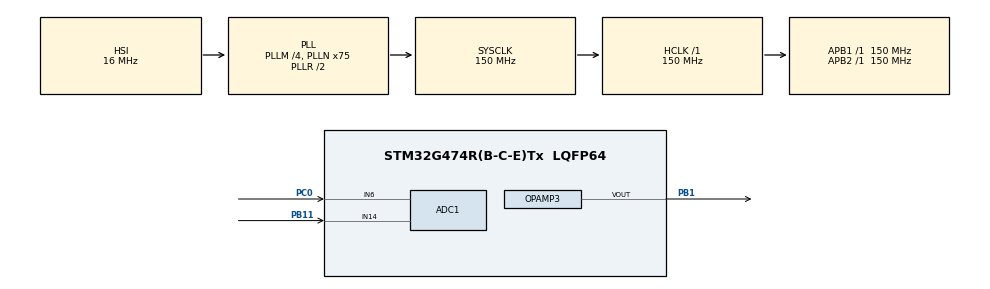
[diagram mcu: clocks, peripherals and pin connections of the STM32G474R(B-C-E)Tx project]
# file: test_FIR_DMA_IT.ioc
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ADC1.Channel-0\#ChannelRegularConversion=ADC_CHANNEL_6
ADC1.ClockPrescaler=ADC_CLOCK_SYNC_PCLK_DIV2
ADC1.DMAContinuousRequests=ENABLE
ADC1.ExternalTrigConv=ADC_EXTERNALTRIG_T1_TRGO
ADC1.GainCompensation=0
ADC1.NbrOfConversionFlag=1
ADC1.OffsetNumber-0\#ChannelRegularConversion=ADC_OFFSET_NONE
ADC1.Overrun=ADC_OVR_DATA_OVERWRITTEN
ADC1.Rank-0\#ChannelRegularConversion=1
ADC1.SamplingTime-0\#ChannelRegularConversion=ADC_SAMPLETIME_47CYCLES_5
ADC1.master=1
DAC3.DAC_Channel-DAC_OUT2_Int=DAC_CHANNEL_2
DAC3.DAC_Trigger_OUT2-DAC_OUT2_Int=DAC_TRIGGER_T1_TRGO
Dma.ADC1.2.Direction=DMA_PERIPH_TO_MEMORY
Dma.ADC1.2.EventEnable=DISABLE
Dma.ADC1.2.Instance=DMA1_Channel4
Dma.ADC1.2.MemDataAlignment=DMA_MDATAALIGN_HALFWORD
Dma.ADC1.2.MemInc=DMA_MINC_ENABLE
Dma.ADC1.2.Mode=DMA_CIRCULAR
Dma.ADC1.2.PeriphDataAlignment=DMA_PDATAALIGN_HALFWORD
Dma.ADC1.2.PeriphInc=DMA_PINC_DISABLE
Dma.ADC1.2.Polarity=HAL_DMAMUX_REQ_GEN_RISING
Dma.ADC1.2.Priority=DMA_PRIORITY_HIGH
Dma.ADC1.2.RequestNumber=1
Dma.ADC1.2.SignalID=NONE
Dma.ADC1.2.SyncEnable=DISABLE
Dma.ADC1.2.SyncPolarity=HAL_DMAMUX_SYNC_NO_EVENT
Dma.ADC1.2.SyncRequestNumber=1
Dma.ADC1.2.SyncSignalID=NONE
Dma.DAC3_CH2.3.Direction=DMA_MEMORY_TO_PERIPH
Dma.DAC3_CH2.3.EventEnable=DISABLE
Dma.DAC3_CH2.3.Instance=DMA1_Channel1
Dma.DAC3_CH2.3.MemDataAlignment=DMA_MDATAALIGN_HALFWORD
Dma.DAC3_CH2.3.MemInc=DMA_MINC_ENABLE
Dma.DAC3_CH2.3.Mode=DMA_CIRCULAR
Dma.DAC3_CH2.3.PeriphDataAlignment=DMA_PDATAALIGN_WORD
Dma.DAC3_CH2.3.PeriphInc=DMA_PINC_DISABLE
Dma.DAC3_CH2.3.Polarity=HAL_DMAMUX_REQ_GEN_RISING
Dma.DAC3_CH2.3.Priority=DMA_PRIORITY_VERY_HIGH
Dma.DAC3_CH2.3.RequestNumber=1
Dma.DAC3_CH2.3.SignalID=NONE
Dma.DAC3_CH2.3.SyncEnable=DISABLE
Dma.DAC3_CH2.3.SyncPolarity=HAL_DMAMUX_SYNC_NO_EVENT
Dma.DAC3_CH2.3.SyncRequestNumber=1
Dma.DAC3_CH2.3.SyncSignalID=NONE
Dma.FMAC_PRELOAD.0.Direction=DMA_MEMORY_TO_MEMORY
Dma.FMAC_PRELOAD.0.EventEnable=DISABLE
Dma.FMAC_PRELOAD.0.Instance=DMA1_Channel3
Dma.FMAC_PRELOAD.0.MemDataAlignment=DMA_MDATAALIGN_WORD
Dma.FMAC_PRELOAD.0.MemInc=DMA_MINC_DISABLE
Dma.FMAC_PRELOAD.0.Mode=DMA_NORMAL
Dma.FMAC_PRELOAD.0.PeriphDataAlignment=DMA_PDATAALIGN_HALFWORD
Dma.FMAC_PRELOAD.0.PeriphInc=DMA_PINC_ENABLE
Dma.FMAC_PRELOAD.0.Polarity=HAL_DMAMUX_REQ_GEN_RISING
Dma.FMAC_PRELOAD.0.Priority=DMA_PRIORITY_HIGH
Dma.FMAC_PRELOAD.0.RequestNumber=1
Dma.FMAC_PRELOAD.0.SignalID=NONE
Dma.FMAC_PRELOAD.0.SyncEnable=DISABLE
Dma.FMAC_PRELOAD.0.SyncPolarity=HAL_DMAMUX_SYNC_NO_EVENT
Dma.FMAC_PRELOAD.0.SyncRequestNumber=1
Dma.FMAC_PRELOAD.0.SyncSignalID=NONE
Dma.FMAC_WRITE.1.Direction=DMA_MEMORY_TO_PERIPH
Dma.FMAC_WRITE.1.EventEnable=DISABLE
Dma.FMAC_WRITE.1.Instance=DMA1_Channel2
Dma.FMAC_WRITE.1.MemDataAlignment=DMA_MDATAALIGN_HALFWORD
Dma.FMAC_WRITE.1.MemInc=DMA_MINC_ENABLE
Dma.FMAC_WRITE.1.Mode=DMA_NORMAL
Dma.FMAC_WRITE.1.PeriphDataAlignment=DMA_PDATAALIGN_WORD
Dma.FMAC_WRITE.1.PeriphInc=DMA_PINC_DISABLE
Dma.FMAC_WRITE.1.Polarity=HAL_DMAMUX_REQ_GEN_RISING
Dma.FMAC_WRITE.1.Priority=DMA_PRIORITY_HIGH
Dma.FMAC_WRITE.1.RequestNumber=1
Dma.FMAC_WRITE.1.SignalID=NONE
Dma.FMAC_WRITE.1.SyncEnable=DISABLE
Dma.FMAC_WRITE.1.SyncPolarity=HAL_DMAMUX_SYNC_NO_EVENT
Dma.FMAC_WRITE.1.SyncRequestNumber=1
Dma.FMAC_WRITE.1.SyncSignalID=NONE
Dma.Request0=FMAC_PRELOAD
Dma.Request1=FMAC_WRITE
Dma.Request2=ADC1
Dma.Request3=DAC3_CH2
Mcu.Family=STM32G4
Mcu.Name=STM32G474R(B-C-E)Tx
Mcu.Package=LQFP64
NVIC.DMA1_Channel1_IRQn=true\:0\:0\:false\:false\:true\:false\:true
NVIC.DMA1_Channel2_IRQn=true\:0\:0\:false\:false\:true\:false\:true
NVIC.DMA1_Channel3_IRQn=true\:0\:0\:false\:false\:true\:false\:true
NVIC.DMA1_Channel4_IRQn=true\:0\:0\:false\:false\:true\:false\:true
NVIC.FMAC_IRQn=true\:0\:0\:false\:false\:true\:true\:true
NVIC.PriorityGroup=NVIC_PRIORITYGROUP_4
OPAMP3.PowerMode=OPAMP_POWERMODE_HIGHSPEED
PB1.Mode=Follower-DAC_OUT2-INP
PB1.Signal=OPAMP3_VOUT
PB11.Mode=IN14-Single-Ended
PB11.Signal=ADC1_IN14
PC0.Mode=IN6-Single-Ended
PC0.Signal=ADC1_IN6
ProjectManager.HeapSize=0x200
ProjectManager.StackSize=0x400
ProjectManager.TargetToolchain=MDK-ARM V5.27
RCC.ADC12Freq_Value=150000000
RCC.ADC345Freq_Value=150000000
RCC.AHBFreq_Value=150000000
RCC.APB1Freq_Value=150000000
RCC.APB1TimFreq_Value=150000000
RCC.APB2Freq_Value=150000000
RCC.APB2TimFreq_Value=150000000
RCC.CortexFreq_Value=150000000
RCC.EXTERNAL_CLOCK_VALUE=12288000
RCC.HCLKFreq_Value=150000000
RCC.HSE_VALUE=24000000
RCC.HSI48_VALUE=48000000
RCC.HSI_VALUE=16000000
RCC.LSE_VALUE=32768
RCC.PLLM=RCC_PLLM_DIV4
RCC.PLLN=75
RCC.SYSCLKFreq_VALUE=150000000
RCC.SYSCLKSource=RCC_SYSCLKSOURCE_PLLCLK
RCC.USBFreq_Value=150000000
RCC.VCOOutputFreq_Value=300000000
TIM1.PeriodNoDither=49
TIM1.Prescaler=14
TIM1.TIM_MasterOutputTrigger=TIM_TRGO_UPDATE
VP_DAC3_VS_DACI2.Mode=DAC_OUT2_Int
VP_FMAC_VS_FMAC.Mode=FMAC_Activate
VP_SYS_VS_DBSignals.Mode=DisableDeadBatterySignals
VP_TIM1_VS_ClockSourceINT.Mode=Internal
board=custom

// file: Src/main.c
/* USER CODE BEGIN Header */
/**
  ******************************************************************************
  * @file           : main.c
  * @brief          : Main program body
  ******************************************************************************
  * @attention
  *
  * <h2><center>&copy; Copyright (c) 2020 STMicroelectronics.
  * All rights reserved.</center></h2>
  *
  * This software component is licensed by ST under BSD 3-Clause license,
  * the "License"; You may not use this file except in compliance with the
  * License. You may obtain a copy of the License at:
  *                        opensource.org/licenses/BSD-3-Clause
  *
  ******************************************************************************
  */
/* USER CODE END Header */

#include "main.h"

/* USER CODE BEGIN Includes */
#include "stm32g4xx_nucleo.h"
#include "private_vars.h"
/* USER CODE END Includes */

/* USER CODE BEGIN PD */
/* Definitions of environment analog values */
  /* Value of analog reference voltage (Vref+), connected to analog voltage   */
  /* supply Vdda (unit: mV).                                                  */
  #define VDDA_APPLI                       (3300U)
/* USER CODE END PD */

ADC_HandleTypeDef hadc1;
DMA_HandleTypeDef hdma_adc1;

DAC_HandleTypeDef hdac3;
DMA_HandleTypeDef hdma_dac3_ch2;

FMAC_HandleTypeDef hfmac;
DMA_HandleTypeDef hdma_fmac_preload;
DMA_HandleTypeDef hdma_fmac_write;

OPAMP_HandleTypeDef hopamp3;

TIM_HandleTypeDef htim1;

/* USER CODE BEGIN PV */
/* FMAC configuration structure */
FMAC_FilterConfigTypeDef sFmacConfig;

/* USER CODE END PV */

void SystemClock_Config(void);
static void MX_GPIO_Init(void);
static void MX_DMA_Init(void);
static void MX_FMAC_Init(void);
static void MX_ADC1_Init(void);
static void MX_DAC3_Init(void);
static void MX_OPAMP3_Init(void);
static void MX_TIM1_Init(void);

int main(void)
{

  /* MCU Configuration--------------------------------------------------------*/

  /* Reset of all peripherals, Initializes the Flash interface and the Systick. */
  HAL_Init();

  /* Configure the system clock */
  SystemClock_Config();

  /* USER CODE BEGIN SysInit */
  /* Configure LED2 */
  BSP_LED_Init(LED2);
  /* USER CODE END SysInit */

  /* Initialize all configured peripherals */
  MX_GPIO_Init();
  MX_DMA_Init();
  MX_FMAC_Init();
  MX_ADC1_Init();
  MX_DAC3_Init();
  MX_OPAMP3_Init();
  MX_TIM1_Init();
  /* USER CODE BEGIN 2 */
  /**********************--======  FMAC  ======--***********************/
  /*## Configure the FMAC peripheral ###########################################*/
  sFmacConfig.InputBaseAddress  = INPUT_BUFFER_BASE;
  sFmacConfig.InputBufferSize   = INPUT_BUFFER_SIZE;
  sFmacConfig.InputThreshold    = INPUT_THRESHOLD;
  sFmacConfig.CoeffBaseAddress  = COEFFICIENT_BUFFER_BASE;
  sFmacConfig.CoeffBufferSize   = COEFFICIENT_BUFFER_SIZE;
  sFmacConfig.OutputBaseAddress = OUTPUT_BUFFER_BASE;
  sFmacConfig.OutputBufferSize  = OUTPUT_BUFFER_SIZE;
  sFmacConfig.OutputThreshold   = OUTPUT_THRESHOLD;
  sFmacConfig.pCoeffA           = NULL;
  sFmacConfig.CoeffASize        = 0;
  sFmacConfig.pCoeffB           = aFilterCoeffB;
  sFmacConfig.CoeffBSize        = COEFF_VECTOR_B_SIZE;
  sFmacConfig.Filter            = FMAC_FUNC_CONVO_FIR;
  sFmacConfig.InputAccess       = FMAC_BUFFER_ACCESS_DMA;
  sFmacConfig.OutputAccess      = FMAC_BUFFER_ACCESS_IT;
#if defined(CLIP_ENABLED)
  sFmacConfig.Clip              = FMAC_CLIP_ENABLED;
#else
  sFmacConfig.Clip              = FMAC_CLIP_DISABLED;
#endif
  sFmacConfig.P                 = COEFF_VECTOR_B_SIZE;
  sFmacConfig.Q                 = FILTER_PARAM_Q_NOT_USED;
  sFmacConfig.R                 = GAIN;

  if (HAL_FMAC_FilterConfig_DMA(&hfmac, &sFmacConfig) != HAL_OK)
  {
    /* Configuration Error */
    Error_Handler();
  }

  while(FilterConfigCallbackCount == 0);

  /*## Preload the dummy input ####################################*/
  if (HAL_FMAC_FilterPreload_DMA(&hfmac, aInputDummyValues, INPUT_DUMMY_ARRAY_SIZE, NULL, 0) != HAL_OK)
  {
    /* Configuration Error */
    Error_Handler();
  }

  while(FilterPreloadCallbackCount == 0);

  /*  Before starting a new process, you need to check the current state of the peripheral;
      if it's busy you need to wait for the end of current transfer before starting the calculation.
      For simplicity reasons, this example is just waiting till the end of the
      process, but the application may perform other tasks while the transfer is ongoing. */
  while (HAL_FMAC_GetState(&hfmac) != HAL_FMAC_STATE_READY)
  {
  }

  /*## Start calculation of FIR filter in DMA/IT mode ##########################*/
  ExpectedCalculatedFilteredDataSize = ADC_BUF_LENGTH / 2;
  if (HAL_FMAC_FilterStart(&hfmac, uhFilteredData, &ExpectedCalculatedFilteredDataSize) != HAL_OK)
  {
    /* Processing Error */
    Error_Handler();
  }

  /**********************--======  ADCs  ======--***********************/
//  uhADCxConvertedData = VAR_CONVERTED_DATA_INIT_VALUE;
  /* Run the ADC calibration in single-ended mode */
  if (HAL_ADCEx_Calibration_Start(&hadc1, ADC_SINGLE_ENDED) != HAL_OK)
  {
    /* Calibration Error */
    Error_Handler();
  }
  /*## Start ADC conversions ###############################################*/
  /* Start ADC group regular conversion with DMA */
  if (HAL_ADC_Start_DMA(&hadc1, (uint32_t *)uhADCxConvertedData, ADC_BUF_LENGTH ) != HAL_OK)
  {
    /* ADC conversion start error */
    Error_Handler();
  }

  /* Start DAC conversion with DMA */
  if (HAL_DAC_Start_DMA(&hdac3, DAC_CHANNEL_2, (uint32_t *)uhFilteredData, ADC_BUF_LENGTH, DAC_ALIGN_12B_R ) != HAL_OK)
  {
    /* DAC conversion start error */
    Error_Handler();
  }

  /* Start OPAMP */
  if (HAL_OPAMP_Start(&hopamp3) != HAL_OK)
  {
    /* OPAMP enable error */
    Error_Handler();
  }

  /* Start Timer trigger */
  if (HAL_TIM_Base_Start(&htim1) != HAL_OK)
  {
    /* Counter enable error */
    Error_Handler();
  }

  /* There is no error in the output values: Turn LED2 on */
  BSP_LED_On(LED2);

  /* USER CODE END 2 */

  /* Infinite loop */
  while (1)
  {

  }
}

void SystemClock_Config(void)
{
  RCC_OscInitTypeDef RCC_OscInitStruct = {0};
  RCC_ClkInitTypeDef RCC_ClkInitStruct = {0};
  RCC_PeriphCLKInitTypeDef PeriphClkInit = {0};

  /** Configure the main internal regulator output voltage
  */
  HAL_PWREx_ControlVoltageScaling(PWR_REGULATOR_VOLTAGE_SCALE1);
  /** Initializes the CPU, AHB and APB busses clocks
  */
  RCC_OscInitStruct.OscillatorType = RCC_OSCILLATORTYPE_HSI;
  RCC_OscInitStruct.HSIState = RCC_HSI_ON;
  RCC_OscInitStruct.HSICalibrationValue = RCC_HSICALIBRATION_DEFAULT;
  RCC_OscInitStruct.PLL.PLLState = RCC_PLL_ON;
  RCC_OscInitStruct.PLL.PLLSource = RCC_PLLSOURCE_HSI;
  RCC_OscInitStruct.PLL.PLLM = RCC_PLLM_DIV4;
  RCC_OscInitStruct.PLL.PLLN = 75;
  RCC_OscInitStruct.PLL.PLLP = RCC_PLLP_DIV2;
  RCC_OscInitStruct.PLL.PLLQ = RCC_PLLQ_DIV2;
  RCC_OscInitStruct.PLL.PLLR = RCC_PLLR_DIV2;
  if (HAL_RCC_OscConfig(&RCC_OscInitStruct) != HAL_OK)
  {
    Error_Handler();
  }
  /** Initializes the CPU, AHB and APB busses clocks
  */
  RCC_ClkInitStruct.ClockType = RCC_CLOCKTYPE_HCLK|RCC_CLOCKTYPE_SYSCLK
                              |RCC_CLOCKTYPE_PCLK1|RCC_CLOCKTYPE_PCLK2;
  RCC_ClkInitStruct.SYSCLKSource = RCC_SYSCLKSOURCE_PLLCLK;
  RCC_ClkInitStruct.AHBCLKDivider = RCC_SYSCLK_DIV1;
  RCC_ClkInitStruct.APB1CLKDivider = RCC_HCLK_DIV1;
  RCC_ClkInitStruct.APB2CLKDivider = RCC_HCLK_DIV1;

  if (HAL_RCC_ClockConfig(&RCC_ClkInitStruct, FLASH_LATENCY_7) != HAL_OK)
  {
    Error_Handler();
  }
  /** Initializes the peripherals clocks
  */
  PeriphClkInit.PeriphClockSelection = RCC_PERIPHCLK_ADC12;
  PeriphClkInit.Adc12ClockSelection = RCC_ADC12CLKSOURCE_SYSCLK;
  if (HAL_RCCEx_PeriphCLKConfig(&PeriphClkInit) != HAL_OK)
  {
    Error_Handler();
  }
}

static void MX_ADC1_Init(void)
{

  ADC_MultiModeTypeDef multimode = {0};
  ADC_ChannelConfTypeDef sConfig = {0};

  /** Common config
  */
  hadc1.Instance = ADC1;
  hadc1.Init.ClockPrescaler = ADC_CLOCK_SYNC_PCLK_DIV2;
  hadc1.Init.Resolution = ADC_RESOLUTION_12B;
  hadc1.Init.DataAlign = ADC_DATAALIGN_RIGHT;
  hadc1.Init.GainCompensation = 0;
  hadc1.Init.ScanConvMode = ADC_SCAN_DISABLE;
  hadc1.Init.EOCSelection = ADC_EOC_SINGLE_CONV;
  hadc1.Init.LowPowerAutoWait = DISABLE;
  hadc1.Init.ContinuousConvMode = DISABLE;
  hadc1.Init.NbrOfConversion = 1;
  hadc1.Init.DiscontinuousConvMode = DISABLE;
  hadc1.Init.ExternalTrigConv = ADC_EXTERNALTRIG_T1_TRGO;
  hadc1.Init.ExternalTrigConvEdge = ADC_EXTERNALTRIGCONVEDGE_RISING;
  hadc1.Init.DMAContinuousRequests = ENABLE;
  hadc1.Init.Overrun = ADC_OVR_DATA_OVERWRITTEN;
  hadc1.Init.OversamplingMode = DISABLE;
  if (HAL_ADC_Init(&hadc1) != HAL_OK)
  {
    Error_Handler();
  }
  /** Configure the ADC multi-mode
  */
  multimode.Mode = ADC_MODE_INDEPENDENT;
  if (HAL_ADCEx_MultiModeConfigChannel(&hadc1, &multimode) != HAL_OK)
  {
    Error_Handler();
  }
  /** Configure Regular Channel
  */
  sConfig.Channel = ADC_CHANNEL_6;
  sConfig.Rank = ADC_REGULAR_RANK_1;
  sConfig.SamplingTime = ADC_SAMPLETIME_47CYCLES_5;
  sConfig.SingleDiff = ADC_SINGLE_ENDED;
  sConfig.OffsetNumber = ADC_OFFSET_NONE;
  sConfig.Offset = 0;
  if (HAL_ADC_ConfigChannel(&hadc1, &sConfig) != HAL_OK)
  {
    Error_Handler();
  }

}

static void MX_DAC3_Init(void)
{

  DAC_ChannelConfTypeDef sConfig = {0};

  /** DAC Initialization
  */
  hdac3.Instance = DAC3;
  if (HAL_DAC_Init(&hdac3) != HAL_OK)
  {
    Error_Handler();
  }
  /** DAC channel OUT2 config
  */
  sConfig.DAC_HighFrequency = DAC_HIGH_FREQUENCY_INTERFACE_MODE_AUTOMATIC;
  sConfig.DAC_DMADoubleDataMode = DISABLE;
  sConfig.DAC_SignedFormat = DISABLE;
  sConfig.DAC_SampleAndHold = DAC_SAMPLEANDHOLD_DISABLE;
  sConfig.DAC_Trigger = DAC_TRIGGER_T1_TRGO;
  sConfig.DAC_Trigger2 = DAC_TRIGGER_NONE;
  sConfig.DAC_OutputBuffer = DAC_OUTPUTBUFFER_DISABLE;
  sConfig.DAC_ConnectOnChipPeripheral = DAC_CHIPCONNECT_ENABLE;
  sConfig.DAC_UserTrimming = DAC_TRIMMING_FACTORY;
  if (HAL_DAC_ConfigChannel(&hdac3, &sConfig, DAC_CHANNEL_2) != HAL_OK)
  {
    Error_Handler();
  }

}

static void MX_FMAC_Init(void)
{

  hfmac.Instance = FMAC;
  if (HAL_FMAC_Init(&hfmac) != HAL_OK)
  {
    Error_Handler();
  }

}

static void MX_OPAMP3_Init(void)
{

  hopamp3.Instance = OPAMP3;
  hopamp3.Init.PowerMode = OPAMP_POWERMODE_HIGHSPEED;
  hopamp3.Init.Mode = OPAMP_FOLLOWER_MODE;
  hopamp3.Init.NonInvertingInput = OPAMP_NONINVERTINGINPUT_DAC;
  hopamp3.Init.InternalOutput = DISABLE;
  hopamp3.Init.TimerControlledMuxmode = OPAMP_TIMERCONTROLLEDMUXMODE_DISABLE;
  hopamp3.Init.UserTrimming = OPAMP_TRIMMING_FACTORY;
  if (HAL_OPAMP_Init(&hopamp3) != HAL_OK)
  {
    Error_Handler();
  }

}

static void MX_TIM1_Init(void)
{

  TIM_ClockConfigTypeDef sClockSourceConfig = {0};
  TIM_MasterConfigTypeDef sMasterConfig = {0};
  TIM_BreakDeadTimeConfigTypeDef sBreakDeadTimeConfig = {0};

  htim1.Instance = TIM1;
  htim1.Init.Prescaler = 14;
  htim1.Init.CounterMode = TIM_COUNTERMODE_UP;
  htim1.Init.Period = 49;
  htim1.Init.ClockDivision = TIM_CLOCKDIVISION_DIV1;
  htim1.Init.RepetitionCounter = 0;
  htim1.Init.AutoReloadPreload = TIM_AUTORELOAD_PRELOAD_DISABLE;
  if (HAL_TIM_Base_Init(&htim1) != HAL_OK)
  {
    Error_Handler();
  }
  sClockSourceConfig.ClockSource = TIM_CLOCKSOURCE_INTERNAL;
  if (HAL_TIM_ConfigClockSource(&htim1, &sClockSourceConfig) != HAL_OK)
  {
    Error_Handler();
  }
  sMasterConfig.MasterOutputTrigger = TIM_TRGO_UPDATE;
  sMasterConfig.MasterOutputTrigger2 = TIM_TRGO2_RESET;
  sMasterConfig.MasterSlaveMode = TIM_MASTERSLAVEMODE_DISABLE;
  if (HAL_TIMEx_MasterConfigSynchronization(&htim1, &sMasterConfig) != HAL_OK)
  {
    Error_Handler();
  }
  sBreakDeadTimeConfig.BreakAFMode = TIM_BREAK_AFMODE_INPUT;
  sBreakDeadTimeConfig.Break2AFMode = TIM_BREAK_AFMODE_INPUT;
  if (HAL_TIMEx_ConfigBreakDeadTime(&htim1, &sBreakDeadTimeConfig) != HAL_OK)
  {
    Error_Handler();
  }

}

static void MX_DMA_Init(void)
{

  /* DMA controller clock enable */
  __HAL_RCC_DMAMUX1_CLK_ENABLE();
  __HAL_RCC_DMA1_CLK_ENABLE();

  /* DMA interrupt init */
  /* DMA1_Channel1_IRQn interrupt configuration */
  HAL_NVIC_SetPriority(DMA1_Channel1_IRQn, 0, 0);
  HAL_NVIC_EnableIRQ(DMA1_Channel1_IRQn);
  /* DMA1_Channel2_IRQn interrupt configuration */
  HAL_NVIC_SetPriority(DMA1_Channel2_IRQn, 0, 0);
  HAL_NVIC_EnableIRQ(DMA1_Channel2_IRQn);
  /* DMA1_Channel3_IRQn interrupt configuration */
  HAL_NVIC_SetPriority(DMA1_Channel3_IRQn, 0, 0);
  HAL_NVIC_EnableIRQ(DMA1_Channel3_IRQn);
  /* DMA1_Channel4_IRQn interrupt configuration */
  HAL_NVIC_SetPriority(DMA1_Channel4_IRQn, 0, 0);
  HAL_NVIC_EnableIRQ(DMA1_Channel4_IRQn);

}

static void MX_GPIO_Init(void)
{

  /* GPIO Ports Clock Enable */
  __HAL_RCC_GPIOC_CLK_ENABLE();
  __HAL_RCC_GPIOB_CLK_ENABLE();

}

/* USER CODE BEGIN 4 */
/**
  * @brief FMAC filter configuration callback
  * @par hfmac: FMAC HAL handle
  * @retval None
  */
void HAL_FMAC_FilterConfigCallback(FMAC_HandleTypeDef *hfmac)
{
  FilterConfigCallbackCount++;;
}

/**
  * @brief FMAC filter preload callback
  * @par hfmac: FMAC HAL handle
  * @retval None
  */
void HAL_FMAC_FilterPreloadCallback(FMAC_HandleTypeDef *hfmac)
{
  FilterPreloadCallbackCount++;;
}

/**
  * @brief FMAC output data ready callback
  * @par hfmac: FMAC HAL handle
  * @retval None
  */
void HAL_FMAC_OutputDataReadyCallback(FMAC_HandleTypeDef *hfmac)
{
  OutputDataReadyCallbackCount++;
}

/**
  * @brief FMAC error callback
  * @par hfmac: FMAC HAL handle
  * @retval None
  */
void HAL_FMAC_ErrorCallback(FMAC_HandleTypeDef *hfmac)
{
  ErrorCount++;
}

/**
  * @brief  Conversion complete callback in non-blocking mode.
  * @param hadc ADC handle
  * @retval None
  */
void HAL_ADC_ConvCpltCallback(ADC_HandleTypeDef *hadc)
{
	ExpectedCalculatedFilteredDataSize = ADC_BUF_LENGTH / 2;;
	if (HAL_FMAC_ConfigFilterOutputBuffer(&hfmac, uhFilteredData + (ADC_BUF_LENGTH / 2), &ExpectedCalculatedFilteredDataSize) != HAL_OK)
	{
		ErrorCount++;
	}
	CurrentInputArraySize = ADC_BUF_LENGTH / 2;
	if (HAL_FMAC_AppendFilterData(&hfmac, uhADCxConvertedData + (ADC_BUF_LENGTH / 2), &CurrentInputArraySize) != HAL_OK)
	{
		ErrorCount++;
	}
}

/**
  * @brief  Conversion DMA half-transfer callback in non-blocking mode.
  * @param hadc ADC handle
  * @retval None
  */
void HAL_ADC_ConvHalfCpltCallback(ADC_HandleTypeDef *hadc)
{
	ExpectedCalculatedFilteredDataSize = ADC_BUF_LENGTH / 2;;
	if (HAL_FMAC_ConfigFilterOutputBuffer(&hfmac, uhFilteredData, &ExpectedCalculatedFilteredDataSize) != HAL_OK)
	{
		ErrorCount++;
	}
	CurrentInputArraySize = ADC_BUF_LENGTH / 2;
	if (HAL_FMAC_AppendFilterData(&hfmac, uhADCxConvertedData, &CurrentInputArraySize) != HAL_OK)
	{
		ErrorCount++;
	}
}

/* USER CODE END 4 */

void Error_Handler(void)
{
  /* USER CODE BEGIN Error_Handler_Debug */
  /* User can add his own implementation to report the HAL error return state */
  while(1)
  {
    /* LED2 is blinking */
    BSP_LED_Toggle(LED2);
    HAL_Delay(500);
  }
  /* USER CODE END Error_Handler_Debug */
}

/************************ (C) COPYRIGHT STMicroelectronics *****END OF FILE****/
